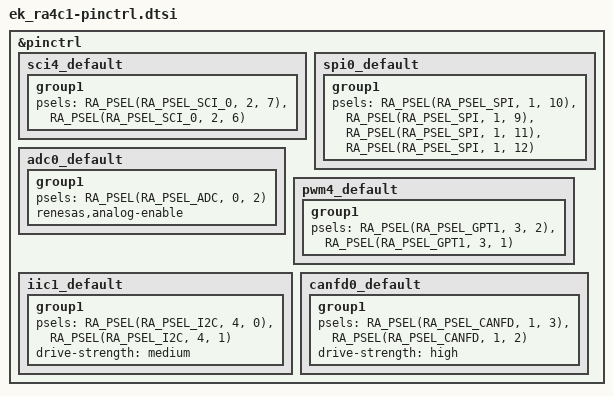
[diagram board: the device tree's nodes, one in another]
/*
 * Copyright (c) 2025 Renesas Electronics Corporation
 * SPDX-License-Identifier: Apache-2.0
 */

&pinctrl {
	sci4_default: sci4_default {
		group1 {
			/* tx rx */
			psels = <RA_PSEL(RA_PSEL_SCI_0, 2, 7)>,
				<RA_PSEL(RA_PSEL_SCI_0, 2, 6)>;
		};
	};

	spi0_default: spi0_default {
		group1 {
			/* MISO MOSI RSPCK SSL */
			psels = <RA_PSEL(RA_PSEL_SPI, 1, 10)>,
				<RA_PSEL(RA_PSEL_SPI, 1, 9)>,
				<RA_PSEL(RA_PSEL_SPI, 1, 11)>,
				<RA_PSEL(RA_PSEL_SPI, 1, 12)>;
		};
	};

	adc0_default: adc0_default {
		group1 {
			/* input */
			psels = <RA_PSEL(RA_PSEL_ADC, 0, 2)>;
			renesas,analog-enable;
		};
	};

	pwm4_default: pwm4_default {
		group1 {
			/* GTIOC4A GTIOC4B */
			psels = <RA_PSEL(RA_PSEL_GPT1, 3, 2)>,
				<RA_PSEL(RA_PSEL_GPT1, 3, 1)>;
		};
	};

	iic1_default: iic1_default {
		group1 {
			/* SCL1 SDA1 */
			psels = <RA_PSEL(RA_PSEL_I2C, 4, 0)>,
				<RA_PSEL(RA_PSEL_I2C, 4, 1)>;
			drive-strength = "medium";
		};
	};

	canfd0_default: canfd0_default {
		group1 {
			/* CRX0 CTX0 */
			psels = <RA_PSEL(RA_PSEL_CANFD, 1, 3)>,
				<RA_PSEL(RA_PSEL_CANFD, 1, 2)>;
			drive-strength = "high";
		};
	};
};
